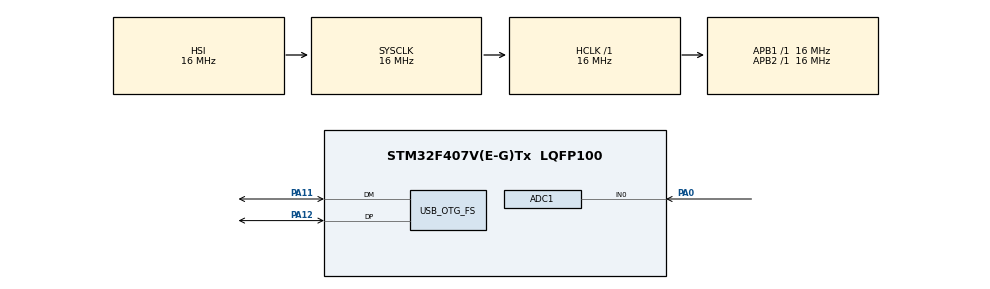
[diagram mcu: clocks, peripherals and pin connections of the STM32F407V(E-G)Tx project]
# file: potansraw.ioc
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Mcu.Family=STM32F4
USB_DEVICE.CLASS_NAME_FS=CDC
PH0-OSC_IN.Signal=RCC_OSC_IN
Dma.ADC1.0.Instance=DMA2_Stream0
RCC.CortexFreq_Value=16000000
ADC1.Rank-0\#ChannelRegularConversion=1
ADC1.ContinuousConvMode=ENABLE
USB_DEVICE.VirtualModeFS=Cdc_FS
PA11.Mode=Device_Only
USB_DEVICE.VirtualMode-CDC_FS=Cdc
ProjectManager.StackSize=0x400
PA0-WKUP.Signal=ADCx_IN0
Dma.ADC1.0.PeriphDataAlignment=DMA_PDATAALIGN_HALFWORD
PA12.Signal=USB_OTG_FS_DP
ProjectManager.TargetToolchain=STM32CubeIDE
Dma.ADC1.0.Mode=DMA_CIRCULAR
VP_USB_DEVICE_VS_USB_DEVICE_CDC_FS.Mode=CDC_FS
Dma.ADC1.0.Priority=DMA_PRIORITY_LOW
Dma.ADC1.0.Direction=DMA_PERIPH_TO_MEMORY
NVIC.DMA2_Stream0_IRQn=true\:0\:0\:false\:false\:true\:false\:true
RCC.LSE_VALUE=32768
Dma.ADC1.0.MemDataAlignment=DMA_MDATAALIGN_HALFWORD
RCC.AHBFreq_Value=16000000
PH0-OSC_IN.Mode=HSE-External-Oscillator
ADC1.Channel-0\#ChannelRegularConversion=ADC_CHANNEL_0
RCC.HSE_VALUE=8000000
board=custom
RCC.VCOOutputFreq_Value=144000000
RCC.APB2Freq_Value=16000000
Dma.ADC1.0.PeriphInc=DMA_PINC_DISABLE
PH1-OSC_OUT.Signal=RCC_OSC_OUT
SH.ADCx_IN0.0=ADC1_IN0,IN0
ADC1.DMAContinuousRequests=ENABLE
Mcu.Name=STM32F407V(E-G)Tx
ADC1.SamplingTime-0\#ChannelRegularConversion=ADC_SAMPLETIME_3CYCLES
PH1-OSC_OUT.Mode=HSE-External-Oscillator
RCC.48MHZClocksFreq_Value=48000000
RCC.SYSCLKFreq_VALUE=16000000
Mcu.Package=LQFP100
ADC1.master=1
PA12.Mode=Device_Only
NVIC.OTG_FS_IRQn=true\:0\:0\:false\:false\:true\:false\:true
PA11.Signal=USB_OTG_FS_DM
Dma.ADC1.0.MemInc=DMA_MINC_ENABLE
USB_OTG_FS.VirtualMode=Device_Only
ProjectManager.HeapSize=0x200
RCC.HSI_VALUE=16000000
RCC.PLLQ=3
NVIC.PriorityGroup=NVIC_PRIORITYGROUP_4
ADC1.NbrOfConversionFlag=1
RCC.PLLM=4
RCC.PLLN=72
Dma.ADC1.0.FIFOMode=DMA_FIFOMODE_DISABLE
RCC.APB1Freq_Value=16000000
Dma.Request0=ADC1

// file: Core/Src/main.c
/* USER CODE BEGIN Header */
/**
  ******************************************************************************
  * @file           : main.c
  * @brief          : Main program body
  ******************************************************************************
  * @attention
  *
  * <h2><center>&copy; Copyright (c) 2021 STMicroelectronics.
  * All rights reserved.</center></h2>
  *
  * This software component is licensed by ST under BSD 3-Clause license,
  * the "License"; You may not use this file except in compliance with the
  * License. You may obtain a copy of the License at:
  *                        opensource.org/licenses/BSD-3-Clause
  *
  ******************************************************************************
  */
/* USER CODE END Header */
#include "main.h"
#include "usb_device.h"

/* USER CODE BEGIN Includes */
#include "usbd_cdc_if.h"
#include "stdio.h"
#include "string.h"
/* USER CODE END Includes */

ADC_HandleTypeDef hadc1;
DMA_HandleTypeDef hdma_adc1;

void SystemClock_Config(void);
static void MX_GPIO_Init(void);
static void MX_DMA_Init(void);
static void MX_ADC1_Init(void);
/* USER CODE BEGIN PFP */
#define ADC_BUF_LEN 4096
uint16_t adc_buf[ADC_BUF_LEN];
uint8_t adccomplete=0;
/* USER CODE END PFP */

int main(void)
{
  /* USER CODE BEGIN 1 */
	 uint16_t raw;
	  char msg[10];
  /* USER CODE END 1 */

  /* MCU Configuration--------------------------------------------------------*/

  /* Reset of all peripherals, Initializes the Flash interface and the Systick. */
  HAL_Init();

  /* Configure the system clock */
  SystemClock_Config();

  /* Initialize all configured peripherals */
  MX_GPIO_Init();
  MX_DMA_Init();
  MX_USB_DEVICE_Init();
  MX_ADC1_Init();
  /* USER CODE BEGIN 2 */
HAL_ADC_Start_DMA(&hadc1,adc_buf,ADC_BUF_LEN);
  /* USER CODE END 2 */

  /* Infinite loop */
  while (1)
  {

    /* USER CODE BEGIN 3 */
	//  HAL_ADC_Start(&hadc1);
		//  HAL_ADC_PollForConversion(&hadc1, HAL_MAX_DELAY);
		//  raw = HAL_ADC_GetValue(&hadc1);//0 and 4096-> 2^12

	  // Convert to string and print
		sprintf(msg, "%hu\r\n", adc_buf[4094]);
	//  HAL_UART_Transmit(&huart2, (uint8_t*)msg, strlen(msg), HAL_MAX_DELAY);
	  /*send data over usb, we have 1000 16bit samples which is 2000bytes*/
		if (adccomplete==1)
		{
	  CDC_Transmit_FS((uint8_t*)msg,strlen(msg));
	  adccomplete=0;
		}

  }
  /* USER CODE END 3 */
}

void SystemClock_Config(void)
{
  RCC_OscInitTypeDef RCC_OscInitStruct = {0};
  RCC_ClkInitTypeDef RCC_ClkInitStruct = {0};

  /** Configure the main internal regulator output voltage
  */
  __HAL_RCC_PWR_CLK_ENABLE();
  __HAL_PWR_VOLTAGESCALING_CONFIG(PWR_REGULATOR_VOLTAGE_SCALE1);
  /** Initializes the RCC Oscillators according to the specified parameters
  * in the RCC_OscInitTypeDef structure.
  */
  RCC_OscInitStruct.OscillatorType = RCC_OSCILLATORTYPE_HSI|RCC_OSCILLATORTYPE_HSE;
  RCC_OscInitStruct.HSEState = RCC_HSE_ON;
  RCC_OscInitStruct.HSIState = RCC_HSI_ON;
  RCC_OscInitStruct.HSICalibrationValue = RCC_HSICALIBRATION_DEFAULT;
  RCC_OscInitStruct.PLL.PLLState = RCC_PLL_ON;
  RCC_OscInitStruct.PLL.PLLSource = RCC_PLLSOURCE_HSE;
  RCC_OscInitStruct.PLL.PLLM = 4;
  RCC_OscInitStruct.PLL.PLLN = 72;
  RCC_OscInitStruct.PLL.PLLP = RCC_PLLP_DIV2;
  RCC_OscInitStruct.PLL.PLLQ = 3;
  if (HAL_RCC_OscConfig(&RCC_OscInitStruct) != HAL_OK)
  {
    Error_Handler();
  }
  /** Initializes the CPU, AHB and APB buses clocks
  */
  RCC_ClkInitStruct.ClockType = RCC_CLOCKTYPE_HCLK|RCC_CLOCKTYPE_SYSCLK
                              |RCC_CLOCKTYPE_PCLK1|RCC_CLOCKTYPE_PCLK2;
  RCC_ClkInitStruct.SYSCLKSource = RCC_SYSCLKSOURCE_HSI;
  RCC_ClkInitStruct.AHBCLKDivider = RCC_SYSCLK_DIV1;
  RCC_ClkInitStruct.APB1CLKDivider = RCC_HCLK_DIV1;
  RCC_ClkInitStruct.APB2CLKDivider = RCC_HCLK_DIV1;

  if (HAL_RCC_ClockConfig(&RCC_ClkInitStruct, FLASH_LATENCY_0) != HAL_OK)
  {
    Error_Handler();
  }
}

static void MX_ADC1_Init(void)
{

  ADC_ChannelConfTypeDef sConfig = {0};

  /** Configure the global features of the ADC (Clock, Resolution, Data Alignment and number of conversion)
  */
  hadc1.Instance = ADC1;
  hadc1.Init.ClockPrescaler = ADC_CLOCK_SYNC_PCLK_DIV2;
  hadc1.Init.Resolution = ADC_RESOLUTION_12B;
  hadc1.Init.ScanConvMode = DISABLE;
  hadc1.Init.ContinuousConvMode = ENABLE;
  hadc1.Init.DiscontinuousConvMode = DISABLE;
  hadc1.Init.ExternalTrigConvEdge = ADC_EXTERNALTRIGCONVEDGE_NONE;
  hadc1.Init.ExternalTrigConv = ADC_SOFTWARE_START;
  hadc1.Init.DataAlign = ADC_DATAALIGN_RIGHT;
  hadc1.Init.NbrOfConversion = 1;
  hadc1.Init.DMAContinuousRequests = ENABLE;
  hadc1.Init.EOCSelection = ADC_EOC_SINGLE_CONV;
  if (HAL_ADC_Init(&hadc1) != HAL_OK)
  {
    Error_Handler();
  }
  /** Configure for the selected ADC regular channel its corresponding rank in the sequencer and its sample time.
  */
  sConfig.Channel = ADC_CHANNEL_0;
  sConfig.Rank = 1;
  sConfig.SamplingTime = ADC_SAMPLETIME_3CYCLES;
  if (HAL_ADC_ConfigChannel(&hadc1, &sConfig) != HAL_OK)
  {
    Error_Handler();
  }

}

static void MX_DMA_Init(void)
{

  /* DMA controller clock enable */
  __HAL_RCC_DMA2_CLK_ENABLE();

  /* DMA interrupt init */
  /* DMA2_Stream0_IRQn interrupt configuration */
  HAL_NVIC_SetPriority(DMA2_Stream0_IRQn, 0, 0);
  HAL_NVIC_EnableIRQ(DMA2_Stream0_IRQn);

}

static void MX_GPIO_Init(void)
{

  /* GPIO Ports Clock Enable */
  __HAL_RCC_GPIOH_CLK_ENABLE();
  __HAL_RCC_GPIOA_CLK_ENABLE();

}

/* USER CODE BEGIN 4 */
 void HAL_ADC_ConvCpltCallback(ADC_HandleTypeDef* hadc)
{
	 adccomplete=1;
}

/**
  * @brief  Regular conversion half DMA transfer callback in non blocking mode
  * @param  hadc pointer to a ADC_HandleTypeDef structure that contains
  *         the configuration information for the specified ADC.
  * @retval None
  */
void HAL_ADC_ConvHalfCpltCallback(ADC_HandleTypeDef* hadc)
{

}
/* USER CODE END 4 */

void Error_Handler(void)
{
  __disable_irq();
  while (1)
  {
  }
}

/************************ (C) COPYRIGHT STMicroelectronics *****END OF FILE****/
